# ICSSM_ICSSM_PR1_PROTECT_SLV_48024C00h register map
Vendor: Texas Instruments
Peripheral module from a debugger description file (folder AM263X).
Registers are 32-bit, read-write, reset 0x0 unless marked. A register's access mark holds for its fields unless they carry their own. Offsets are as the file gives them; lines under a group give offsets from that group; [hi:lo] are bit positions; {n}, {i} and the like mark numbered series; 'fields as' and 'values as' point back to an identical list; <NAME> marks a mode.

## ICSSM_PR1_PROTECT_SLV
0x00 ICSSM_PR1_PROTECT_SLV_UNLOCK_KEY
  [31:0] UNLOCK_KEY — UnLock Key Pattern 0x83E7_0B13 to UnLock 0x0000_0000 to Lock Must unlock to update MMRs
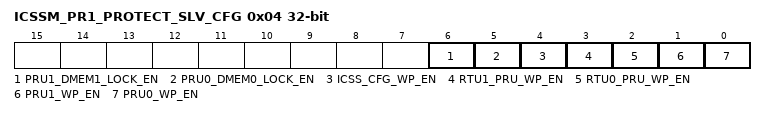
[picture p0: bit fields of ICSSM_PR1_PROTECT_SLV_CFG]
0x04 ICSSM_PR1_PROTECT_SLV_CFG — Config.
  [6] PRU1_DMEM1_LOCK_EN — Write Protect DMEM10:disable1:enable When enabled only PRU1 can write to DMEM1
  [5] PRU0_DMEM0_LOCK_EN — Write Protect DMEM00:disable1:enable When enabled only PRU0 can write to DMEM0
  [4] ICSS_CFG_WP_EN — Write Protect ICSS_CFG0:disable1:enable
  [3] RTU1_PRU_WP_EN — Write Protect RTU1_PRU access Debug IMEM0:disable1:enable
  [2] RTU0_PRU_WP_EN — Write Protect RTU0_PRU access Debug IMEM0:disable1:enable
  [1] PRU1_WP_EN — Write Protect PRU1 access Debug IMEM0:disable1:enable
  [0] PRU0_WP_EN — Write Protect PRU0 access Debug IMEM0:disable1:enable
